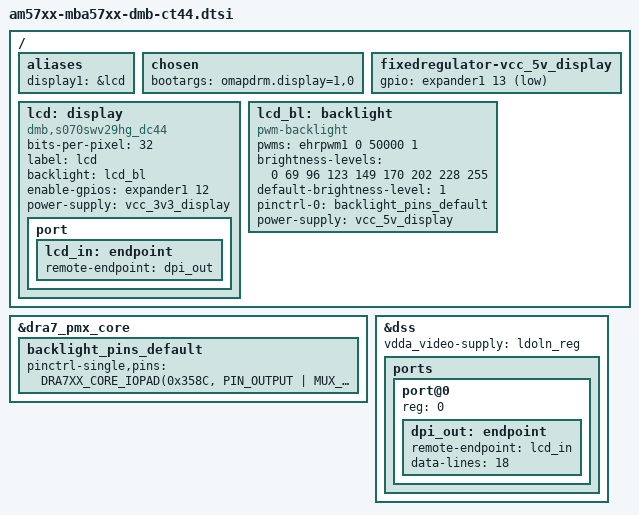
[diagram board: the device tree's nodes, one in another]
/*
 * Copyright (C) 2020 TQ-Systems GmbH
 *
 * Author: Michael Krummsdorf <michael.krummsdorf@tq-group.com>
 *
 * This program is free software; you can redistribute it and/or modify
 * it under the terms of the GNU General Public License version 2 as
 * published by the Free Software Foundation.
 */

/ {
	aliases {
		display1 = &lcd;
	};

	chosen {
		bootargs = "omapdrm.display=1,0";
	};

	fixedregulator-vcc_5v_display {
		gpio = <&expander1 13 GPIO_ACTIVE_LOW>;
	};

	/* S070WV106H-CT44 */
	lcd: display {
		compatible = "dmb,s070swv29hg_dc44", "simple-panel";
		bits-per-pixel = <32>; /* 32: RGB888/666 mode */
		label = "lcd";
		backlight = <&lcd_bl>;
		/* lcd power enable LCD_PWR_EN */
		enable-gpios = <&expander1 12 GPIO_ACTIVE_HIGH>;
		power-supply = <&vcc_3v3_display>;
		status = "okay";

		port {
			lcd_in: endpoint {
				remote-endpoint = <&dpi_out>;
			};
		};
	};

	lcd_bl: backlight {
		compatible = "pwm-backlight";
		pwms = <&ehrpwm1 0 50000 1>;
		brightness-levels = <0 69 96 123 149 170 202 228 255>;
		default-brightness-level = <1>;
		pinctrl-names = "default";
		pinctrl-0 = <&backlight_pins_default>;
		power-supply = <&vcc_5v_display>;
	};
};

&dra7_pmx_core {
	backlight_pins_default: backlight_pins_default {
		pinctrl-single,pins = <
			DRA7XX_CORE_IOPAD(0x358C, PIN_OUTPUT | MUX_MODE10) /* vin2a_d9.ehrpwm2A */
		>;
	};
};

/* display subsystem */
&dss {
	status = "okay";
	vdda_video-supply = <&ldoln_reg>;

	ports {
		#address-cells = <1>;
		#size-cells = <0>;

		port@0 {
			reg = <0>;
			dpi_out: endpoint {
				remote-endpoint = <&lcd_in>;
				data-lines = <18>;
			};
		};
	};
};
